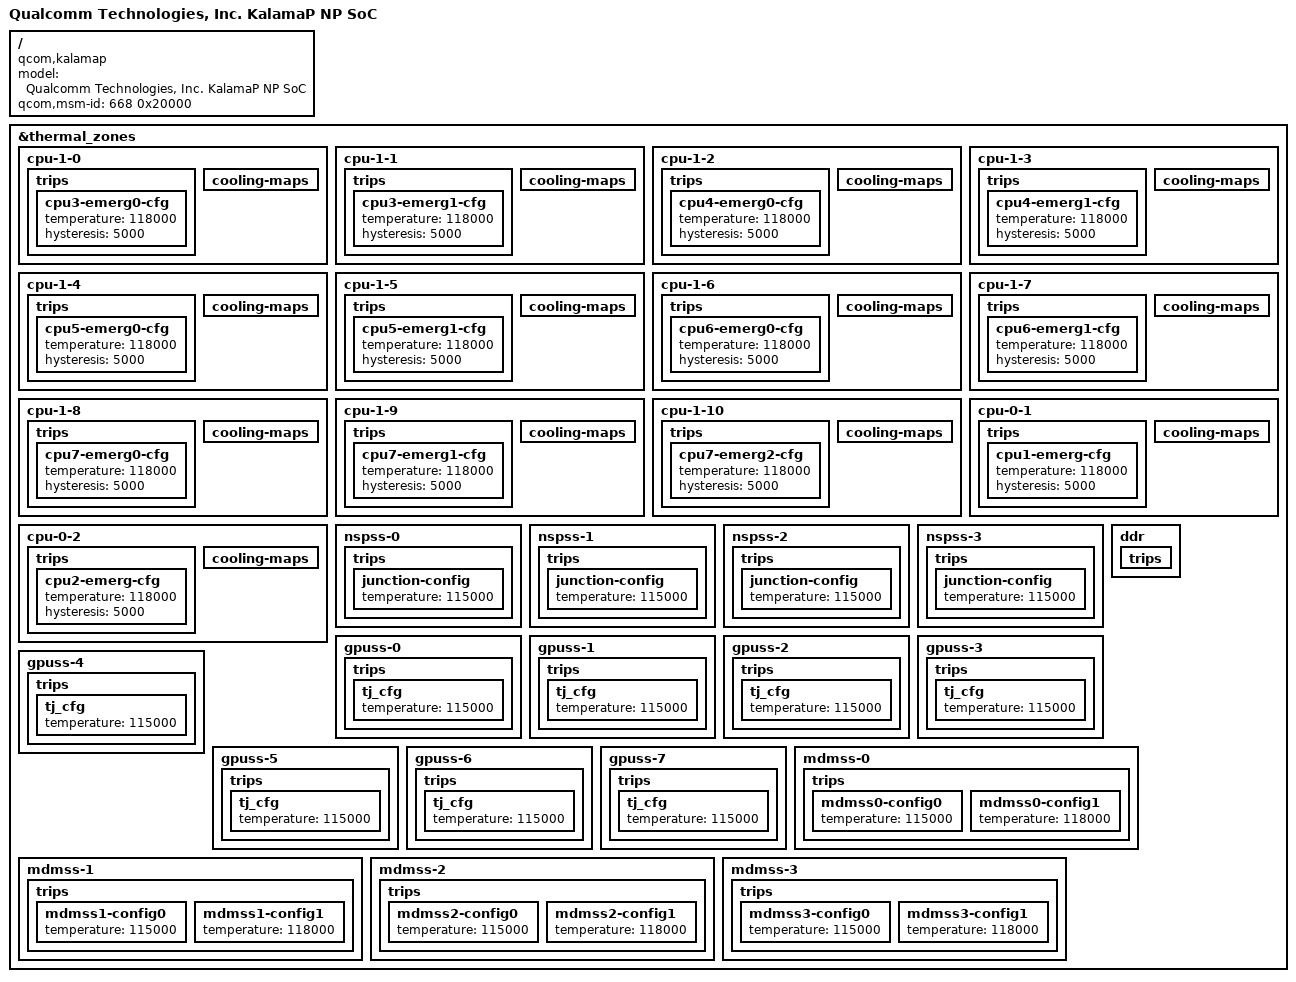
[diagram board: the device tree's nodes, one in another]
#include "kalamap-qcs.dtsi"

/ {
	model = "Qualcomm Technologies, Inc. KalamaP NP SoC";
	compatible = "qcom,kalamap";
	qcom,msm-id = <668 0x20000>;
};

&thermal_zones {
	cpu-1-0 {
		trips {
			cpu3-emerg0-cfg {
				temperature = <118000>;
				hysteresis = <5000>;
			};

			/delete-node/ cpu3-emerg0-1-cfg;
			/delete-node/ reset-mon-cfg;
		};

		cooling-maps {
			/delete-node/ cpu10_cdev1;
		};
	};

	cpu-1-1 {
		trips {
			cpu3-emerg1-cfg {
				temperature = <118000>;
				hysteresis = <5000>;
			};

			/delete-node/ cpu3-emerg1-1-cfg;
			/delete-node/ reset-mon-cfg;
		};

		cooling-maps {
			/delete-node/ cpu11_cdev1;
		};
	};

	cpu-1-2 {
		trips {
			cpu4-emerg0-cfg {
				temperature = <118000>;
				hysteresis = <5000>;
			};

			/delete-node/ cpu4-emerg0-1-cfg;
			/delete-node/ reset-mon-cfg;
		};

		cooling-maps {
			/delete-node/ cpu12_cdev1;
		};
	};

	cpu-1-3 {
		trips {
			cpu4-emerg1-cfg {
				temperature = <118000>;
				hysteresis = <5000>;
			};

			/delete-node/ cpu4-emerg1-1-cfg;
			/delete-node/ reset-mon-cfg;
		};

		cooling-maps {
			/delete-node/ cpu13_cdev1;
		};
	};

	cpu-1-4 {
		trips {
			cpu5-emerg0-cfg {
				temperature = <118000>;
				hysteresis = <5000>;
			};

			/delete-node/ cpu5-emerg0-1-cfg;
			/delete-node/ reset-mon-cfg;
		};

		cooling-maps {
			/delete-node/ cpu14_cdev1;
		};
	};

	cpu-1-5 {
		trips {
			cpu5-emerg1-cfg {
				temperature = <118000>;
				hysteresis = <5000>;
			};

			/delete-node/ cpu5-emerg1-1-cfg;
			/delete-node/ reset-mon-cfg;
		};

		cooling-maps {
			/delete-node/ cpu15_cdev1;
		};
	};

	cpu-1-6 {
		trips {
			cpu6-emerg0-cfg {
				temperature = <118000>;
				hysteresis = <5000>;
			};

			/delete-node/ cpu6-emerg0-1-cfg;
			/delete-node/ reset-mon-cfg;
		};

		cooling-maps {
			/delete-node/ cpu16_cdev1;
		};
	};

	cpu-1-7 {
		trips {
			cpu6-emerg1-cfg {
				temperature = <118000>;
				hysteresis = <5000>;
			};

			/delete-node/ cpu6-emerg1-1-cfg;
			/delete-node/ reset-mon-cfg;
		};

		cooling-maps {
			/delete-node/ cpu17_cdev1;
		};
	};

	cpu-1-8 {
		trips {
			cpu7-emerg0-cfg {
				temperature = <118000>;
				hysteresis = <5000>;
			};

			/delete-node/ cpu7-emerg0-1-cfg;
			/delete-node/ reset-mon-cfg;
		};

		cooling-maps {
			/delete-node/ cpu18_cdev1;
		};
	};

	cpu-1-9 {
		trips {
			cpu7-emerg1-cfg {
				temperature = <118000>;
				hysteresis = <5000>;
			};

			/delete-node/ cpu7-emerg1-1-cfg;
			/delete-node/ reset-mon-cfg;
		};

		cooling-maps {
			/delete-node/ cpu19_cdev1;
		};
	};

	cpu-1-10 {
		trips {
			cpu7-emerg2-cfg {
				temperature = <118000>;
				hysteresis = <5000>;
			};

			/delete-node/ cpu7-emerg2-1-cfg;
			/delete-node/ reset-mon-cfg;
		};

		cooling-maps {
			/delete-node/ cpu110_cdev1;
		};
	};

	cpu-0-1 {
		trips {
			cpu1-emerg-cfg {
				temperature = <118000>;
				hysteresis = <5000>;
			};

			/delete-node/ cpu1-emerg1-cfg;
			/delete-node/ reset-mon-cfg;
		};

		cooling-maps {
			/delete-node/ cpu01_cdev1;
		};
	};

	cpu-0-2 {
		trips {
			cpu2-emerg-cfg {
				temperature = <118000>;
				hysteresis = <5000>;
			};

			/delete-node/ cpu2-emerg1-cfg;
			/delete-node/ reset-mon-cfg;
		};

		cooling-maps {
			/delete-node/ cpu02_cdev1;
		};
	};

	nspss-0 {
		trips {
			junction-config {
				temperature = <115000>;
			};

			/delete-node/ reset-mon-cfg;
		};
	};

	nspss-1 {
		trips {
			junction-config {
				temperature = <115000>;
			};

			/delete-node/ reset-mon-cfg;
		};
	};

	nspss-2 {
		trips {
			junction-config {
				temperature = <115000>;
			};

			/delete-node/ reset-mon-cfg;
		};
	};

	nspss-3 {
		trips {
			junction-config {
				temperature = <115000>;
			};

			/delete-node/ reset-mon-cfg;
		};
	};

	ddr {
		trips {
			/delete-node/ ddr0-config;
			/delete-node/ reset-mon-cfg;
		};

		/delete-node/ cooling-maps;
	};

	gpuss-0 {
		trips {
			tj_cfg {
				temperature = <115000>;
			};

			/delete-node/ reset-mon-cfg;
		};
	};

	gpuss-1 {
		trips {
			tj_cfg {
				temperature = <115000>;
			};

			/delete-node/ reset-mon-cfg;
		};
	};

	gpuss-2 {
		trips {
			tj_cfg {
				temperature = <115000>;
			};

			/delete-node/ reset-mon-cfg;
		};
	};

	gpuss-3 {
		trips {
			tj_cfg {
				temperature = <115000>;
			};

			/delete-node/ reset-mon-cfg;
		};
	};

	gpuss-4 {
		trips {
			tj_cfg {
				temperature = <115000>;
			};

			/delete-node/ reset-mon-cfg;
		};
	};

	gpuss-5 {
		trips {
			tj_cfg {
				temperature = <115000>;
			};

			/delete-node/ reset-mon-cfg;
		};
	};

	gpuss-6 {
		trips {
			tj_cfg {
				temperature = <115000>;
			};

			/delete-node/ reset-mon-cfg;
		};
	};

	gpuss-7 {
		trips {
			tj_cfg {
				temperature = <115000>;
			};

			/delete-node/ reset-mon-cfg;
		};
	};

	mdmss-0 {
		trips {
			mdmss0-config0 {
				temperature = <115000>;
			};

			mdmss0-config1 {
				temperature = <118000>;
			};

			/delete-node/ reset-mon-cfg;
		};
	};

	mdmss-1 {
		trips {
			mdmss1-config0 {
				temperature = <115000>;
			};

			mdmss1-config1 {
				temperature = <118000>;
			};

			/delete-node/ reset-mon-cfg;
		};
	};

	mdmss-2 {
		trips {
			mdmss2-config0 {
				temperature = <115000>;
			};

			mdmss2-config1 {
				temperature = <118000>;
			};

			/delete-node/ reset-mon-cfg;
		};
	};

	mdmss-3 {
		trips {
			mdmss3-config0 {
				temperature = <115000>;
			};

			mdmss3-config1 {
				temperature = <118000>;
			};

			/delete-node/ reset-mon-cfg;
		};
	};
};
